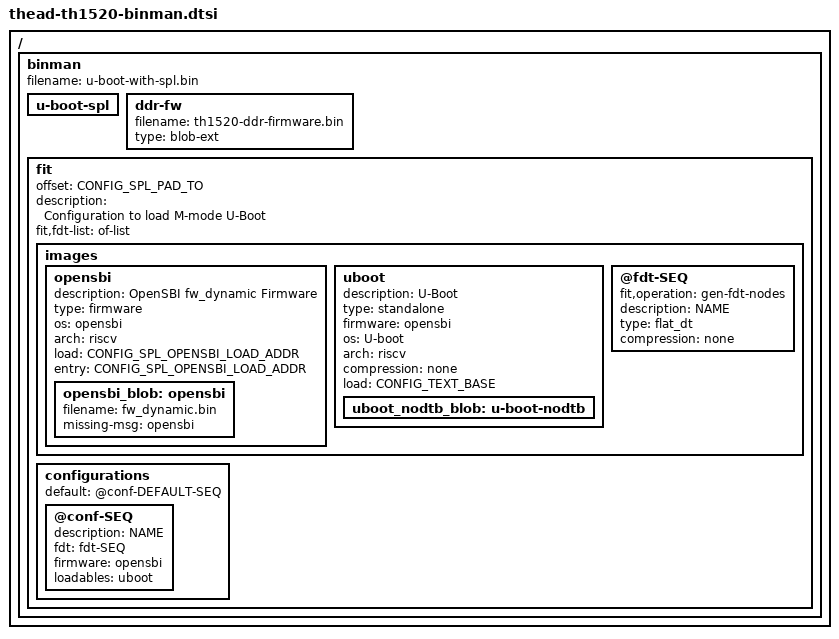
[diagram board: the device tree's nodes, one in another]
// SPDX-License-Identifier: GPL-2.0-only
/*
 * Copyright (c) 2025 Yao Zi <ziyao@disroot.org>
 */

#include <config.h>

/ {
	binman: binman {
	};
};

&binman {
	filename = "u-boot-with-spl.bin";

	u-boot-spl {
	};

	ddr-fw {
		filename = "th1520-ddr-firmware.bin";
		type = "blob-ext";
	};

	fit {
		offset = <CONFIG_SPL_PAD_TO>;

		description = "Configuration to load M-mode U-Boot";

		#address-cells = <2>;
		fit,fdt-list = "of-list";

		images {
			opensbi {
				description = "OpenSBI fw_dynamic Firmware";
				type = "firmware";
				os = "opensbi";
				arch = "riscv";
				load = /bits/ 64 <CONFIG_SPL_OPENSBI_LOAD_ADDR>;
				entry = /bits/ 64 <CONFIG_SPL_OPENSBI_LOAD_ADDR>;

				opensbi_blob: opensbi {
					filename = "fw_dynamic.bin";
					missing-msg = "opensbi";
				};
			};

			uboot {
				description = "U-Boot";
				type = "standalone";
				firmware = "opensbi";
				os = "U-boot";
				arch = "riscv";
				compression = "none";
				load = /bits/ 64 <CONFIG_TEXT_BASE>;

				uboot_nodtb_blob: u-boot-nodtb {
				};
			};

			@fdt-SEQ {
				fit,operation = "gen-fdt-nodes";
				description = "NAME";
				type = "flat_dt";
				compression = "none";
			};
		};

		configurations {
			default = "@conf-DEFAULT-SEQ";

			@conf-SEQ {
				description = "NAME";
				fdt = "fdt-SEQ";
				firmware = "opensbi";
				loadables = "uboot";
			};
		};
	};
};
